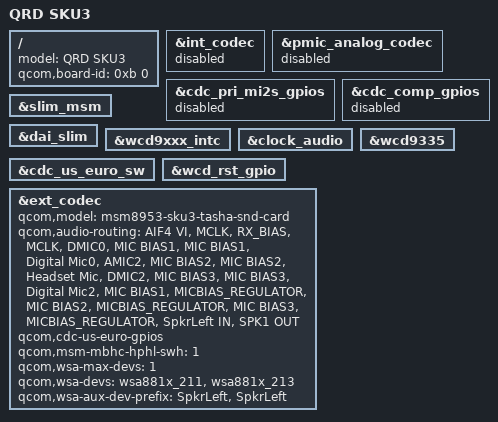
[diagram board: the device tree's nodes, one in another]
/*
 * Copyright (c) 2018, 2020 The Linux Foundation. All rights reserved.
 *
 * This program is free software; you can redistribute it and/or modify
 * it under the terms of the GNU General Public License version 2 and
 * only version 2 as published by the Free Software Foundation.
 *
 * This program is distributed in the hope that it will be useful,
 * but WITHOUT ANY WARRANTY; without even the implied warranty of
 * MERCHANTABILITY or FITNESS FOR A PARTICULAR PURPOSE.  See the
 * GNU General Public License for more details.
 */

/dts-v1/;
/plugin/;

#include "msm8953-qrd-sku3.dtsi"

/ {
	model = "QRD SKU3";
	qcom,board-id = <0xb 0>;
};

&int_codec {
	status = "disabled";
};

&pmic_analog_codec {
	status = "disabled";
};

&cdc_pri_mi2s_gpios {
	status = "disabled";
};

&cdc_comp_gpios {
	status = "disabled";
};

&slim_msm {
	status = "okay";
};

&dai_slim {
	status = "okay";
};

&wcd9xxx_intc {
	status = "okay";
};

&clock_audio {
	status = "okay";
};

&wcd9335 {
	status = "okay";
};

&cdc_us_euro_sw {
	status = "okay";
};

&wcd_rst_gpio {
	status = "okay";
};

&ext_codec {
	qcom,model = "msm8953-sku3-tasha-snd-card";
	status = "okay";

	qcom,audio-routing =
		"AIF4 VI", "MCLK",
		"RX_BIAS", "MCLK",
		"DMIC0", "MIC BIAS1",
		"MIC BIAS1", "Digital Mic0",
		"AMIC2", "MIC BIAS2",
		"MIC BIAS2", "Headset Mic",
		"DMIC2", "MIC BIAS3",
		"MIC BIAS3", "Digital Mic2",
		"MIC BIAS1", "MICBIAS_REGULATOR",
		"MIC BIAS2", "MICBIAS_REGULATOR",
		"MIC BIAS3", "MICBIAS_REGULATOR",
		"SpkrLeft IN", "SPK1 OUT";

	qcom,cdc-us-euro-gpios;

	qcom,msm-mbhc-hphl-swh = <1>;

	qcom,wsa-max-devs = <1>;
	qcom,wsa-devs = <&wsa881x_211>, <&wsa881x_213>;
	qcom,wsa-aux-dev-prefix = "SpkrLeft", "SpkrLeft";
};
